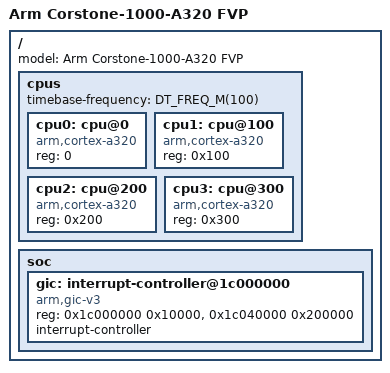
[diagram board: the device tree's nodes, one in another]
/*
 * Copyright (c) 2026 BayLibre SAS
 * Copyright 2026 Arm Limited and/or its affiliates <open-source-office@arm.com>
 * SPDX-License-Identifier: Apache-2.0
 */

/dts-v1/;

#include <arm64/armv9-a.dtsi>
#include "fvp_corstone1000.dtsi"

/ {
	model = "Arm Corstone-1000-A320 FVP";

	cpus {
		#address-cells = <1>;
		#size-cells = <0>;
		timebase-frequency = <DT_FREQ_M(100)>;

		cpu0: cpu@0 {
			compatible = "arm,cortex-a320";
			reg = <0>;
			device_type = "cpu";
		};

		cpu1: cpu@100 {
			compatible = "arm,cortex-a320";
			reg = <0x100>;
			device_type = "cpu";
		};

		cpu2: cpu@200 {
			compatible = "arm,cortex-a320";
			reg = <0x200>;
			device_type = "cpu";
		};

		cpu3: cpu@300 {
			compatible = "arm,cortex-a320";
			reg = <0x300>;
			device_type = "cpu";
		};
	};

	soc {
		gic: interrupt-controller@1c000000 {
			compatible = "arm,gic-v3", "arm,gic";
			reg = <0x1c000000 0x10000>, /* GICD */
			      <0x1c040000 0x200000>; /* GICR */
			interrupt-controller;
			#interrupt-cells = <4>;
			#address-cells = <1>;
			#size-cells = <1>;
			status = "okay";
		};
	};
};
